# SIM3C164_B register map
File version: 1
CPU: 
Registers are 32-bit, read-write, reset 0x0 unless marked. A register's access mark holds for its fields unless they carry their own. Offsets are from the block's base; [hi:lo] are bit positions; {n}, {i} and the like mark numbered series.

## CAPSENSE_0
Base 0x40023000
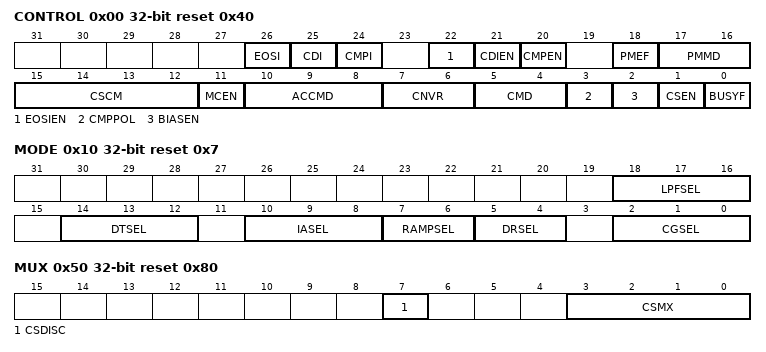
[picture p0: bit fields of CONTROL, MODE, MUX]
0x00 CONTROL reset 0x40 — Module Control
  [26] EOSI ro — End-of-Scan Interrupt Flag.
    0=NOT_SET (The CAPSENSEn module has not completed a scan since the last time EOSI was cleared.); 1=SET (The CAPSENSEn module completed a scan.)
  [25] CDI — Conversion Done Interrupt Flag.
    0=NOT_SET (Read: The CAPSENSEn module has not completed a data conversion since the last time CDI was cleared. Write: Clear the interrupt.); 1=SET (Read: The CAPSENSEn module completed a data conversion. Write: Force a conversion complete interrupt.)
  [24] CMPI ro — Threshold Comparator Interrupt Flag.
    0=NOT_SET (The capacitive sensing result did not cause a compare threshold interrupt.); 1=SET (The capacitive sensing result caused a compare threshold interrupt.)
  [22] EOSIEN — End-of-Scan Interrupt Enable.
    0=DISABLED (Disable the single scan end-of-scan interrupt.); 1=ENABLED (Enable the single scan end-of-scan interrupt.)
  [21] CDIEN — Conversion Done Interrupt Enable.
    0=DISABLED (Disable the single conversion done interrupt.); 1=ENABLED (Enable the single conversion done interrupt.)
  [20] CMPEN — Threshold Comparator Enable.
    0=DISABLED (Disable the threshold comparator.); 1=ENABLED (Enable the threshold comparator.)
  [18] PMEF — Pin Monitor Event Flag.
    0=NOT_SET (A retry did not occur due to a pin monitor event during the last conversion.); 1=SET (A retry occurred due to a pin monitor event during the last conversion.)
  [17:16] PMMD — Pin Monitor Mode.
    0=ALWAYS_RETRY (Always retry on a pin state change.); 1=RETRY_TWICE (Retry up to twice on consecutive bit cycles.); 2=RETRY_FOUR_TIMES (Retry up to four times on consecutive bit cycles.); 3=DO_NOT_RETRY (Ignore monitored signal state change.)
  [15:12] CSCM — Start of Conversion Mode Select.
    0=CSNT0 (The CSnT0 ("On Demand" by writing 1 to CSBUSY) trigger source starts conversions.); 1=CSNT1 (The CSnT1 (Timer 0 Low Overflow) trigger source starts conversions.); 2=CSNT2 (The CSnT2 (Timer 0 High Overflow) trigger source starts conversions.); 3=CSNT3 (The CSnT3 (Timer 1 Low Overflow) trigger source starts conversions.); 4=CSNT4 (The CSnT4 (Timer 1 High Overflow) trigger source starts conversions.); 5=CSNT5 (The CSnT5 (I2C0 Timer Byte 1 Overflow) trigger source starts conversions.); 6=CSNT6 (The CSnT6 (I2C0 Timer Byte 3 Overflow) trigger source starts conversions.); 7=CSNT7 (The CSnT7 (I2C1 Timer Byte 1 Overflow) trigger source starts conversions.); 8=CSNT8 (The CSnT8 (I2C1 Timer Byte 3 Overflow) trigger source starts conversions.); {v}=CSNT{v} (The CSnT{v} (RESERVED) trigger source starts conversions.) (v=9..15)
  [11] MCEN — Multiple Channel Enable.
    0=DISABLED (Disable the multiple channel measurement feature.); 1=ENABLED (Enable the multiple channel measurement feature.)
  [10:8] ACCMD — Accumulator Mode Select.
    0=ACC_1 (Accumulate 1 sample.); 1=ACC_4 (Accumulate 4 samples.); 2=ACC_8 (Accumulate 8 samples.); 3=ACC_16 (Accumulate 16 samples.); 4=ACC_32 (Accumulate 32 samples.); 5=ACC_64 (Accumulate 64 samples.)
  [7:6] CNVR — Conversion Rate.
    0=12BIT (Conversions last 12 internal CAPSENSE clocks and results are 12 bits in length.); 1=13BIT (Conversions last 13 internal CAPSENSE clocks and results are 13 bits in length.); 2=14BIT (Conversions last 14 internal CAPSENSE clocks and results are 14 bits in length.); 3=16BIT (Conversions last 16 internal CAPSENSE clocks and results are 16 bits in length.)
  [5:4] CMD — Conversion Mode Select.
    0=SINGLE (Single Conversion Mode: One conversion occurs on a single channel.); 1=SCAN (Single Scan Mode: One conversion on each channel selected by SCANEN occurs. An end-of-scan interrupt indicates all channels have been measured.); 2=CONT_SINGLE (Continuous Single Conversion Mode: Continuously converts on a single channel. This operation ends only if the module is disabled (CSEN = 0) or if a compare threshold event occurs (CMPI = 1).); 3=CONT_SCAN (Continuous Scan Mode: Continuously loops through and converts on all the channels selected by SCANEN. This operation ends only if the module is disabled (CSEN = 0) or if a compare threshold event occurs (CMPI = 1).)
  [3] CMPPOL — Digital Comparator Polarity Select.
    0=GT (The digital comparator generates an interrupt if the conversion is greater than the CSTH threshold.); 1=LTE (The digital comparator generates an interrupt if the conversion is less than or equal to the CSTH threshold.)
  [2] BIASEN — Bias Enable.
    0=DISABLED (Disable the bias.); 1=ENABLED (Enable the bias.)
  [1] CSEN — Module Enable.
    0=DISABLED (Disable the capacitive sensing module.); 1=ENABLED (Enable the capacitive sensing module.)
  [0] BUSYF — Start and Busy Flag.
    0=IDLE (Read: A capacitive sensing conversion is complete or a conversion is not currently in progress. Write: No effect.); 1=BUSY (Read: A capacitive sensing conversion is in progress. Write: Initiate a capacitive sensing conversion if BUSYF is selected as the start of conversion source.)
0x10 MODE reset 0x7 — Measurement Mode
  [18:16] LPFSEL — Low Pass Filter Select.
  [14:12] DTSEL — Discharge Time Select.
  [10:8] IASEL — Output Current Select.
  [7:6] RAMPSEL — Ramp Selection.
  [5:4] DRSEL — Double Reset Select.
  [2:0] CGSEL — Capacitance Gain Select.
0x20 DATA — Measurement Data
  [15:0] DATA — Capacitive Sensing Data.
0x30 SCAN — Channel Scan Enable
  [15:0] SCANEN — Channel Scan Enable.
0x40 CSTH — Compare Threshold
  [15:0] CSTH — Compare Threshold.
0x50 MUX reset 0x80 — Mux Channel Select
  [7] CSDISC — Channel Disconnect.
    0=CONNECT (Connect the capacitive sensing circuit to the selected channel.); 1=DISCONNECT (Disconnect the capacitive sensing input channel.)
  [3:0] CSMX — Mux Channel Select.
    0=CSN0 (Select CSn.0 (PB0.2).); 1=CSN1 (Select CSn.1 (PB0.3).); 2=CSN2 (Select CSn.2 (PB0.4).); 3=CSN3 (Select CSn.3 (PB0.6).); 4=CSN4 (Select CSn.4 (PB0.7).); 5=CSN5 (Select CSn.5 (RESERVED).); 6=CSN6 (Select CSn.6 (RESERVED).); 7=CSN7 (Select CSn.7 (PB0.0).); 8=CSN8 (Select CSn.8 (RESERVED).); 9=CSN9 (Select CSn.9 (RESERVED).); 10=CSN10 (Select CSn.10 (PB0.12).); 11=CSN11 (Select CSn.11 (PB0.13).); 12=CSN12 (Select CSn.12 (PB0.14).); 13=CSN13 (Select CSn.13 (PB0.15).); 14=CSN14 (Select CSn.14 (PB1.0).); 15=CSN15 (Select CSn.15 (PB1.1).)
